# NUC100DN_v1 register map
File version: 1.0
NUC100DN_v1 SVD file
Registers are 32-bit, read-write, reset 0x0 unless marked. A register's access mark holds for its fields unless they carry their own. Offsets are from the block's base; lines under a group give offsets from that group; [hi:lo] are bit positions; {n}, {i} and the like mark numbered series; 'fields as' and 'values as' point back to an identical list; <NAME> marks a mode.

## Memory map
0x40004000 WDT size 0x8 — WDT Register Map
0x40004100 WWDT size 0x10 — WWDT Register Map
0x40008000 RTC size 0x34 — RTC Register Map
0x40010000 TMR01 blocks up to offset 0x3C — TIMER Register Map
0x40020000 I2C0 blocks up to offset 0x44 — I2C Register Map
0x40030000 SPI0 blocks up to offset 0x48 — SPI Register Map
0x40034000 SPI1 blocks up to offset 0x48 — SPI Register Map
0x40040000 PWMA blocks up to offset 0x98 — PWM Register Map
0x40050000 UART0 size 0x3C — UART Register Map
0x40060000 USB blocks up to offset 0x94 — USB Register Map
0x400D0000 ACMP size 0xC — ACMP Register Map
0x400E0000 ADC blocks up to offset 0x44 — ADC Register Map
0x40100000 PS2 size 0x20 — PS2 Register Map
0x40110000 TMR23 blocks up to offset 0x3C — TIMER Register Map
0x40120000 I2C1 blocks up to offset 0x44 — I2C Register Map
0x40130000 SPI2 blocks up to offset 0x48 — SPI Register Map
0x40134000 SPI3 blocks up to offset 0x48 — SPI Register Map
0x40140000 PWMB blocks up to offset 0x98 — PWM Register Map
0x40150000 UART1 size 0x3C — UART Register Map
0x40154000 UART2 blocks up to offset 0x3C — UART Register Map
0x40190000 SC0 blocks up to offset 0x40 — SC Register Map
0x40194000 SC1 blocks up to offset 0x40 — SC Register Map
0x40198000 SC2 blocks up to offset 0x40 — SC Register Map
0x401A0000 I2S size 0x18 — I2S Register Map
0x50000000 GCR blocks up to offset 0x104 — GCR Register Map
0x50000200 CLK blocks up to offset 0x3C — CLK Register Map
0x50000300 INT size 0x88 — INT Register Map
0x50004000 GPIO blocks up to offset 0x350 — GPIO Register Map
{0x50008000+0x100*n} PDMA_CH{n} blocks up to offset 0x84 (n=0..8) — PDMA Register Map
0x50008E00 CRC blocks up to offset 0x8C — PDMA Register Map
0x50008F00 PDMA_GCR size 0x14 — PDMA Register Map
0x5000C000 FMC blocks up to offset 0x44 — FMC Register Map
0x50010000 EBI size 0x8 — EBI Register Map
0xE000E000 NVIC blocks up to offset 0x420 — NVIC Register Map
0xE000E010 SYST blocks up to offset 0x1C — SYST Register Map
0xE000ED00 SCS blocks up to offset 0xD24 — SCS Register Map

## SYST — SYST Register Map
Base 0xE000E010
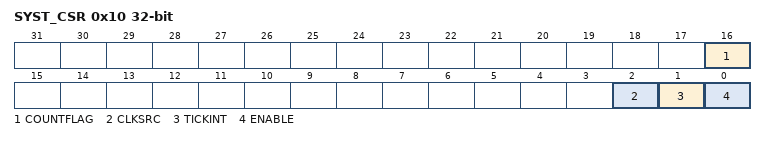
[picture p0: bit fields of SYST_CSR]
0x10 SYST_CSR — SysTick Control and Status Register
  [16] COUNTFLAG — System Tick Counter Flag. Returns 1 If Timer Counted to 0 Since Last Time this Register Was Read. COUNTFLAG is set by a count transition from 1 to 0. COUNTFLAG is cleared on read or by a write to the Current Value register.
  [2] CLKSRC — System Tick Clock Source Selection
    0=Clock source is (optional) external reference clock; 1=Core clock used for SysTick
  [1] TICKINT — System Tick Interrupt Enable Bit
    0=Counting down to 0 does not cause the SysTick exception to be pended. Software can use COUNTFLAG to determine if a count to 0 has occurred; 1=Counting down to 0 will cause the SysTick exception to be pended. Clearing the SysTick Current Value register by a register write in software will not cause SysTick to be pended
  [0] ENABLE — System Tick Counter Enable Bit
    0=Counter Disabled; 1=Counter will operate in a multi-shot manner
0x14 SYST_RVR reset not defined — SysTick Reload Value Register
  [23:0] RELOAD — Value to load into the Current Value register when the counter reaches 0.
0x18 SYST_CVR reset not defined — SysTick Current Value Register
  [23:0] CURRENT — System Tick Current Value. Current counter value. This is the value of the counter at the time it is sampled. The counter does not provide read-modify-write protection. The register is write-clear. A software write of any value will clear the register to 0. Unsupported bits RAZ (see SysTick Reload Value register).
